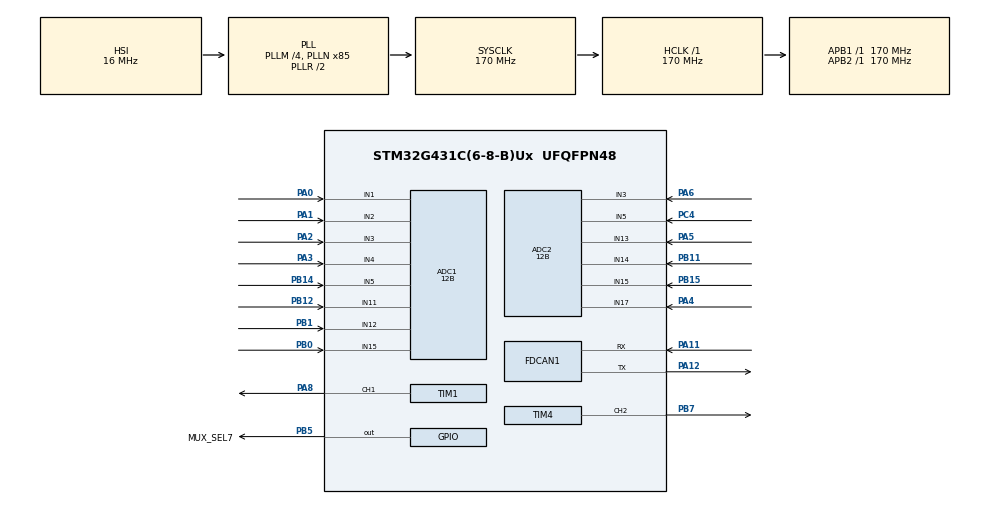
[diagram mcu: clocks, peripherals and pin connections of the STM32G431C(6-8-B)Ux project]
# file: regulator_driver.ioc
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ADC1.Channel-0\#ChannelRegularConversion=ADC_CHANNEL_1
ADC1.Channel-1\#ChannelRegularConversion=ADC_CHANNEL_2
ADC1.Channel-2\#ChannelRegularConversion=ADC_CHANNEL_3
ADC1.Channel-3\#ChannelRegularConversion=ADC_CHANNEL_4
ADC1.Channel-4\#ChannelRegularConversion=ADC_CHANNEL_5
ADC1.Channel-5\#ChannelRegularConversion=ADC_CHANNEL_11
ADC1.Channel-6\#ChannelRegularConversion=ADC_CHANNEL_12
ADC1.Channel-7\#ChannelRegularConversion=ADC_CHANNEL_15
ADC1.ClockPrescaler=ADC_CLOCK_SYNC_PCLK_DIV4
ADC1.ContinuousConvMode=ENABLE
ADC1.DataAlign=ADC_DATAALIGN_RIGHT
ADC1.DiscontinuousConvMode=DISABLE
ADC1.EOCSelection=ADC_EOC_SINGLE_CONV
ADC1.ExternalTrigConv=ADC_SOFTWARE_START
ADC1.ExternalTrigConvEdge=ADC_EXTERNALTRIGCONVEDGE_NONE
ADC1.LowPowerAutoWait=DISABLE
ADC1.Mode=ADC_MODE_INDEPENDENT
ADC1.NbrOfConversion=8
ADC1.NbrOfConversionFlag=1
ADC1.Overrun=ADC_OVR_DATA_OVERWRITTEN
ADC1.OversamplingMode=DISABLE
ADC1.Rank-0\#ChannelRegularConversion=1
ADC1.Rank-1\#ChannelRegularConversion=2
ADC1.Rank-2\#ChannelRegularConversion=3
ADC1.Rank-3\#ChannelRegularConversion=4
ADC1.Rank-4\#ChannelRegularConversion=5
ADC1.Rank-5\#ChannelRegularConversion=6
ADC1.Rank-6\#ChannelRegularConversion=7
ADC1.Rank-7\#ChannelRegularConversion=8
ADC1.Resolution=ADC_RESOLUTION_12B
ADC1.SamplingTime-0\#ChannelRegularConversion=ADC_SAMPLETIME_247CYCLES_5
ADC1.SamplingTime-1\#ChannelRegularConversion=ADC_SAMPLETIME_247CYCLES_5
ADC1.SamplingTime-2\#ChannelRegularConversion=ADC_SAMPLETIME_247CYCLES_5
ADC1.SamplingTime-3\#ChannelRegularConversion=ADC_SAMPLETIME_247CYCLES_5
ADC1.SamplingTime-4\#ChannelRegularConversion=ADC_SAMPLETIME_247CYCLES_5
ADC1.SamplingTime-5\#ChannelRegularConversion=ADC_SAMPLETIME_247CYCLES_5
ADC1.SamplingTime-6\#ChannelRegularConversion=ADC_SAMPLETIME_247CYCLES_5
ADC1.SamplingTime-7\#ChannelRegularConversion=ADC_SAMPLETIME_247CYCLES_5
ADC1.ScanConvMode=ADC_SCAN_ENABLE
ADC1.master=1
ADC2.Channel-0\#ChannelRegularConversion=ADC_CHANNEL_17
ADC2.Channel-1\#ChannelRegularConversion=ADC_CHANNEL_13
ADC2.Channel-2\#ChannelRegularConversion=ADC_CHANNEL_3
ADC2.Channel-3\#ChannelRegularConversion=ADC_CHANNEL_14
ADC2.Channel-4\#ChannelRegularConversion=ADC_CHANNEL_5
ADC2.Channel-5\#ChannelRegularConversion=ADC_CHANNEL_15
ADC2.ClockPrescaler=ADC_CLOCK_SYNC_PCLK_DIV4
ADC2.ContinuousConvMode=ENABLE
ADC2.DataAlign=ADC_DATAALIGN_RIGHT
ADC2.DiscontinuousConvMode=DISABLE
ADC2.EOCSelection=ADC_EOC_SINGLE_CONV
ADC2.ExternalTrigConv=ADC_SOFTWARE_START
ADC2.ExternalTrigConvEdge=ADC_EXTERNALTRIGCONVEDGE_NONE
ADC2.LowPowerAutoWait=DISABLE
ADC2.Mode=ADC_MODE_INDEPENDENT
ADC2.NbrOfConversion=6
ADC2.NbrOfConversionFlag=1
ADC2.Overrun=ADC_OVR_DATA_OVERWRITTEN
ADC2.OversamplingMode=DISABLE
ADC2.Rank-0\#ChannelRegularConversion=1
ADC2.Rank-1\#ChannelRegularConversion=2
ADC2.Rank-2\#ChannelRegularConversion=3
ADC2.Rank-3\#ChannelRegularConversion=4
ADC2.Rank-4\#ChannelRegularConversion=5
ADC2.Rank-5\#ChannelRegularConversion=6
ADC2.Resolution=ADC_RESOLUTION_12B
ADC2.SamplingTime-0\#ChannelRegularConversion=ADC_SAMPLETIME_247CYCLES_5
ADC2.SamplingTime-1\#ChannelRegularConversion=ADC_SAMPLETIME_247CYCLES_5
ADC2.SamplingTime-2\#ChannelRegularConversion=ADC_SAMPLETIME_247CYCLES_5
ADC2.SamplingTime-3\#ChannelRegularConversion=ADC_SAMPLETIME_247CYCLES_5
ADC2.SamplingTime-4\#ChannelRegularConversion=ADC_SAMPLETIME_247CYCLES_5
ADC2.SamplingTime-5\#ChannelRegularConversion=ADC_SAMPLETIME_247CYCLES_5
ADC2.ScanConvMode=ADC_SCAN_ENABLE
FDCAN1.AutoRetransmission=ENABLE
FDCAN1.CalculateBaudRateNominal=499999
FDCAN1.CalculateTimeBitNominal=2000
FDCAN1.CalculateTimeQuantumNominal=117.64705882352942
FDCAN1.ClockDivider=FDCAN_CLOCK_DIV1
FDCAN1.DataPrescaler=1
FDCAN1.DataSyncJumpWidth=1
FDCAN1.DataTimeSeg1=1
FDCAN1.DataTimeSeg2=1
FDCAN1.ExtFiltersNbr=0
FDCAN1.FrameFormat=FDCAN_FRAME_CLASSIC
FDCAN1.Mode=FDCAN_MODE_NORMAL
FDCAN1.NominalPrescaler=20
FDCAN1.NominalSyncJumpWidth=2
FDCAN1.NominalTimeSeg1=14
FDCAN1.NominalTimeSeg2=2
FDCAN1.ProtocolException=DISABLE
FDCAN1.StdFiltersNbr=1
FDCAN1.TransmitPause=DISABLE
FDCAN1.TxFifoQueueMode=FDCAN_TX_FIFO_OPERATION
Mcu.Family=STM32G4
Mcu.Name=STM32G431C(6-8-B)Ux
Mcu.Package=UFQFPN48
NVIC.PriorityGroup=NVIC_PRIORITYGROUP_4
PA0.Mode=IN1-Single-Ended
PA0.Signal=ADC1_IN1
PA1.Mode=IN2-Single-Ended
PA1.Signal=ADC1_IN2
PA11.Mode=FDCAN_Activate
PA11.Signal=FDCAN1_RX
PA12.Mode=FDCAN_Activate
PA12.Signal=FDCAN1_TX
PA2.Mode=IN3-Single-Ended
PA2.Signal=ADC1_IN3
PA3.Mode=IN4-Single-Ended
PA3.Signal=ADC1_IN4
PA4.Mode=IN17-Single-Ended
PA4.Signal=ADC2_IN17
PA5.Mode=IN13-Single-Ended
PA5.Signal=ADC2_IN13
PA6.Mode=IN3-Single-Ended
PA6.Signal=ADC2_IN3
PA8.Signal=S_TIM1_CH1
PB0.Mode=IN15-Single-Ended
PB0.Signal=ADC1_IN15
PB1.Mode=IN12-Single-Ended
PB1.Signal=ADC1_IN12
PB11.Mode=IN14-Single-Ended
PB11.Signal=ADC2_IN14
PB12.Mode=IN11-Single-Ended
PB12.Signal=ADC1_IN11
PB13.Signal=TIM1_CH1N
PB14.Mode=IN5-Single-Ended
PB14.Signal=ADC1_IN5
PB15.Mode=IN15-Single-Ended
PB15.Signal=ADC2_IN15
PB5.GPIO_Label=MUX_SEL7
PB5.GPIO_PuPd=GPIO_NOPULL
PB5.GPIO_Speed=GPIO_SPEED_FREQ_HIGH
PB5.PinState=GPIO_PIN_RESET
PB5.Signal=GPIO_Output
PB7.Signal=S_TIM4_CH2
PC4.Mode=IN5-Single-Ended
PC4.Signal=ADC2_IN5
ProjectManager.HeapSize=0x200
ProjectManager.StackSize=0x400
ProjectManager.TargetToolchain=CMake
RCC.ADC12Freq_Value=170000000
RCC.AHBFreq_Value=170000000
RCC.APB1Freq_Value=170000000
RCC.APB1TimFreq_Value=170000000
RCC.APB2Freq_Value=170000000
RCC.APB2TimFreq_Value=170000000
RCC.CortexFreq_Value=170000000
RCC.EXTERNAL_CLOCK_VALUE=12288000
RCC.HCLKFreq_Value=170000000
RCC.HSE_VALUE=8000000
RCC.HSI48_VALUE=48000000
RCC.HSI_VALUE=16000000
RCC.LSE_VALUE=32768
RCC.PLLM=RCC_PLLM_DIV4
RCC.PLLN=85
RCC.SYSCLKFreq_VALUE=170000000
RCC.SYSCLKSource=RCC_SYSCLKSOURCE_PLLCLK
RCC.USBFreq_Value=170000000
RCC.VCOOutputFreq_Value=340000000
SH.S_TIM1_CH1.0=TIM1_CH1,PWM Generation1 CH1 CH1N
SH.S_TIM4_CH2.0=TIM4_CH2,PWM Generation2 CH2
TIM1.AutoReloadPreload=TIM_AUTORELOAD_PRELOAD_ENABLE
TIM1.Channel-PWM\ Generation1\ CH1\ CH1N=TIM_CHANNEL_1
TIM1.ClockDivision=TIM_CLOCKDIVISION_DIV1
TIM1.CounterMode=TIM_COUNTERMODE_CENTERALIGNED1
TIM1.OCNIdleState_1=TIM_OCNIDLESTATE_RESET
TIM1.OCNPolarity_1=TIM_OCNPOLARITY_HIGH
TIM1.PeriodNoDither=4250
TIM1.Prescaler=0
TIM1.PulseNoDither_1=0
TIM1.TIM_MasterOutputTrigger=TIM_TRGO_RESET
TIM1.TIM_MasterOutputTrigger2=TIM_TRGO2_RESET
TIM4.AutoReloadPreload=TIM_AUTORELOAD_PRELOAD_ENABLE
TIM4.Channel-PWM\ Generation2\ CH2=TIM_CHANNEL_2
TIM4.ClockDivision=TIM_CLOCKDIVISION_DIV1
TIM4.CounterMode=TIM_COUNTERMODE_UP
TIM4.PeriodNoDither=4249
TIM4.Prescaler=0
TIM4.PulseNoDither_2=0
VP_TIM1_VS_ClockSourceINT.Mode=Internal
VP_TIM4_VS_ClockSourceINT.Mode=Internal
board=custom

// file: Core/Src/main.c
/* USER CODE BEGIN Header */
/**
  ******************************************************************************
  * @file           : main.c
  * @brief          : Main program body
  ******************************************************************************
  * @attention
  *
  * Copyright (c) 2026 STMicroelectronics.
  * All rights reserved.
  *
  * This software is licensed under terms that can be found in the LICENSE file
  * in the root directory of this software component.
  * If no LICENSE file comes with this software, it is provided AS-IS.
  *
  ******************************************************************************
  */
/* USER CODE END Header */
#include "main.h"
#include "adc.h"
#include "fdcan.h"
#include "tim.h"
#include "gpio.h"

/* USER CODE BEGIN Includes */
#include "bsp.h"
#include "dl.h"
#include "bl.h"
/* USER CODE END Includes */

void SystemClock_Config(void);

int main(void)
{

  /* MCU Configuration--------------------------------------------------------*/

  /* Reset of all peripherals, Initializes the Flash interface and the Systick. */
  HAL_Init();

  /* Configure the system clock */
  SystemClock_Config();

  /* Initialize all configured peripherals */
  MX_GPIO_Init();
  MX_ADC1_Init();
  MX_ADC2_Init();
  MX_FDCAN1_Init();
  MX_TIM1_Init();
  MX_TIM4_Init();
  /* USER CODE BEGIN 2 */
  /* ── 三层初始化，顺序不能换 ────────────────────────────────────────────────
   *   bsp_init()  板级：引脚、半桥、泄放、ADC、CAN（只配不启动）
   *   dl_init()   数据层：验证测量链路可达
   *   bl_init()   业务层：策略状态机归零 + 注册 CAN 回调 + 启动 FDCAN
   *
   * 三者在结束时的状态：功率级是**断电**的（MOE=0、PERMIT 拉低、P-MOS 断开、
   * 泄放占空比 0），不会因为固件启动就给功率级加电。
   * 要真正运行必须显式调 bl_regulator_request_enable(TRUE)，而且还要过联锁。 */
  (VOID)bsp_init();
  (VOID)dl_init();
  (VOID)bl_init();
  /* USER CODE END 2 */

  /* Infinite loop */
  /* USER CODE BEGIN WHILE */
  U32 last_tick = HAL_GetTick();

  while (1)
  {
    /* USER CODE END WHILE */

    /* USER CODE BEGIN 3 */
    /* 1 ms 节拍：在主循环里按 tick 对齐，不放进 SysTick_Handler。
     * 原因见 bl.h —— bl 里的功率级切换会用 HAL_Delay 轮询电感电流，
     * 放进 SysTick 会自己等自己，直接死锁。 */
    if ((HAL_GetTick() - last_tick) >= 1U)
    {
      last_tick = HAL_GetTick();
      bl_task_handler();
    }

    /* 后台任务：CAN 收发、周期状态帧 */
    bl_task_schedule();
  }
  /* USER CODE END 3 */
}

void SystemClock_Config(void)
{
  RCC_OscInitTypeDef RCC_OscInitStruct = {0};
  RCC_ClkInitTypeDef RCC_ClkInitStruct = {0};

  /** Configure the main internal regulator output voltage
  */
  HAL_PWREx_ControlVoltageScaling(PWR_REGULATOR_VOLTAGE_SCALE1_BOOST);

  /** Initializes the RCC Oscillators according to the specified parameters
  * in the RCC_OscInitTypeDef structure.
  */
  RCC_OscInitStruct.OscillatorType = RCC_OSCILLATORTYPE_HSI;
  RCC_OscInitStruct.HSIState = RCC_HSI_ON;
  RCC_OscInitStruct.HSICalibrationValue = RCC_HSICALIBRATION_DEFAULT;
  RCC_OscInitStruct.PLL.PLLState = RCC_PLL_ON;
  RCC_OscInitStruct.PLL.PLLSource = RCC_PLLSOURCE_HSI;
  RCC_OscInitStruct.PLL.PLLM = RCC_PLLM_DIV4;
  RCC_OscInitStruct.PLL.PLLN = 85;
  RCC_OscInitStruct.PLL.PLLP = RCC_PLLP_DIV2;
  RCC_OscInitStruct.PLL.PLLQ = RCC_PLLQ_DIV2;
  RCC_OscInitStruct.PLL.PLLR = RCC_PLLR_DIV2;
  if (HAL_RCC_OscConfig(&RCC_OscInitStruct) != HAL_OK)
  {
    Error_Handler();
  }

  /** Initializes the CPU, AHB and APB buses clocks
  */
  RCC_ClkInitStruct.ClockType = RCC_CLOCKTYPE_HCLK|RCC_CLOCKTYPE_SYSCLK
                              |RCC_CLOCKTYPE_PCLK1|RCC_CLOCKTYPE_PCLK2;
  RCC_ClkInitStruct.SYSCLKSource = RCC_SYSCLKSOURCE_PLLCLK;
  RCC_ClkInitStruct.AHBCLKDivider = RCC_SYSCLK_DIV1;
  RCC_ClkInitStruct.APB1CLKDivider = RCC_HCLK_DIV1;
  RCC_ClkInitStruct.APB2CLKDivider = RCC_HCLK_DIV1;

  if (HAL_RCC_ClockConfig(&RCC_ClkInitStruct, FLASH_LATENCY_4) != HAL_OK)
  {
    Error_Handler();
  }
}

void Error_Handler(void)
{
  __disable_irq();
  while (1)
  {
  }
}
